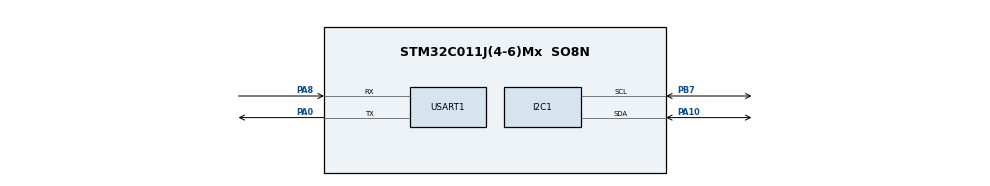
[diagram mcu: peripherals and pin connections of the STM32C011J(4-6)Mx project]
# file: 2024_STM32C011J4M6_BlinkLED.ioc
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I2C1.Timing=0x20303E5D
Mcu.Family=STM32C0
Mcu.Name=STM32C011J(4-6)Mx
Mcu.Package=SO8N
PA0.Mode=Asynchronous
PA0.Signal=USART1_TX
PA10\ [PA12].Mode=I2C
PA10\ [PA12].Signal=I2C1_SDA
PA13.Mode=Serial_Wire
PA13.Signal=DEBUG_SWDIO
PA14-BOOT0.Mode=Serial_Wire
PA14-BOOT0.Signal=DEBUG_SWCLK
PA8.Mode=Asynchronous
PA8.Signal=USART1_RX
PA8__PA11\ [PA9].StandardMode=true
PB7.Mode=I2C
PB7.Signal=I2C1_SCL
PC14-OSCX_IN\ (PC14)__PB7.StandardMode=true
PC15-OSCX_OUT\ (PC15)__PA14-BOOT0__PB6.StandardMode=true
PF2-NRST__PA0__PA1__PA2.StandardMode=true
ProjectManager.HeapSize=0x200
ProjectManager.StackSize=0x400
ProjectManager.TargetToolchain=STM32CubeIDE
RCC.ADCFreq_Value=48000000
RCC.AHBFreq_Value=48000000
RCC.CortexFreq_Value=48000000
RCC.EXTERNAL_CLOCK_VALUE=12288000
RCC.HCLKFreq_Value=48000000
RCC.HSE_VALUE=8000000
RCC.HSISYSCLKDivider=RCC_HSI_DIV1
RCC.HSI_VALUE=48000000
RCC.LSE_VALUE=32768
RCC.SYSCLKFreq_VALUE=48000000
USART1.DMADisableonRxErrorParam=ADVFEATURE_DMA_ENABLEONRXERROR
USART1.OverrunDisableParam=ADVFEATURE_OVERRUN_ENABLE
USART1.SwapParam=ADVFEATURE_SWAP_DISABLE
USART1.VirtualMode-Asynchronous=VM_ASYNC
VP_SYS_VS_PINREMAP_10_12.Mode=PINREMAP_10_12
board=custom

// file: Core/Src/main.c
/* USER CODE BEGIN Header */
/**
  ******************************************************************************
  * @file           : main.c
  * @brief          : Main program body
  ******************************************************************************
  * @attention
  *
  * Copyright (c) 2024 STMicroelectronics.
  * All rights reserved.
  *
  * This software is licensed under terms that can be found in the LICENSE file
  * in the root directory of this software component.
  * If no LICENSE file comes with this software, it is provided AS-IS.
  *
  ******************************************************************************
  */
/* USER CODE END Header */
#include "main.h"

I2C_HandleTypeDef hi2c1;

UART_HandleTypeDef huart1;

void SystemClock_Config(void);
static void MX_GPIO_Init(void);
static void MX_USART1_UART_Init(void);
static void MX_I2C1_Init(void);

int main(void)
{

  /* USER CODE BEGIN 1 */
	uint8_t rxData;
  /* USER CODE END 1 */

  /* MCU Configuration--------------------------------------------------------*/

  /* Reset of all peripherals, Initializes the Flash interface and the Systick. */
  HAL_Init();

  /* Configure the system clock */
  SystemClock_Config();

  /* Initialize all configured peripherals */
  MX_GPIO_Init();
  MX_USART1_UART_Init();
  MX_I2C1_Init();

  /* Infinite loop */
  /* USER CODE BEGIN WHILE */
  while (1)
  {
	  // Check if serial data is available
	  if( HAL_UART_Receive(&huart1, &rxData, 1, HAL_MAX_DELAY) == HAL_OK ) {
	  	  HAL_UART_Transmit(&huart1, &rxData, sizeof(rxData), HAL_MAX_DELAY);
	  }

    /* USER CODE END WHILE */

  }
}

void SystemClock_Config(void)
{
  RCC_OscInitTypeDef RCC_OscInitStruct = {0};
  RCC_ClkInitTypeDef RCC_ClkInitStruct = {0};

  /** Initializes the RCC Oscillators according to the specified parameters
  * in the RCC_OscInitTypeDef structure.
  */
  RCC_OscInitStruct.OscillatorType = RCC_OSCILLATORTYPE_HSI;
  RCC_OscInitStruct.HSIState = RCC_HSI_ON;
  RCC_OscInitStruct.HSIDiv = RCC_HSI_DIV1;
  RCC_OscInitStruct.HSICalibrationValue = RCC_HSICALIBRATION_DEFAULT;
  if (HAL_RCC_OscConfig(&RCC_OscInitStruct) != HAL_OK)
  {
    Error_Handler();
  }

  /** Initializes the CPU, AHB and APB buses clocks
  */
  RCC_ClkInitStruct.ClockType = RCC_CLOCKTYPE_HCLK|RCC_CLOCKTYPE_SYSCLK
                              |RCC_CLOCKTYPE_PCLK1;
  RCC_ClkInitStruct.SYSCLKSource = RCC_SYSCLKSOURCE_HSI;
  RCC_ClkInitStruct.SYSCLKDivider = RCC_SYSCLK_DIV1;
  RCC_ClkInitStruct.AHBCLKDivider = RCC_HCLK_DIV1;
  RCC_ClkInitStruct.APB1CLKDivider = RCC_APB1_DIV1;

  if (HAL_RCC_ClockConfig(&RCC_ClkInitStruct, FLASH_LATENCY_1) != HAL_OK)
  {
    Error_Handler();
  }
}

static void MX_I2C1_Init(void)
{

  hi2c1.Instance = I2C1;
  hi2c1.Init.Timing = 0x20303E5D;
  hi2c1.Init.OwnAddress1 = 0;
  hi2c1.Init.AddressingMode = I2C_ADDRESSINGMODE_7BIT;
  hi2c1.Init.DualAddressMode = I2C_DUALADDRESS_DISABLE;
  hi2c1.Init.OwnAddress2 = 0;
  hi2c1.Init.OwnAddress2Masks = I2C_OA2_NOMASK;
  hi2c1.Init.GeneralCallMode = I2C_GENERALCALL_DISABLE;
  hi2c1.Init.NoStretchMode = I2C_NOSTRETCH_DISABLE;
  if (HAL_I2C_Init(&hi2c1) != HAL_OK)
  {
    Error_Handler();
  }

  /** Configure Analogue filter
  */
  if (HAL_I2CEx_ConfigAnalogFilter(&hi2c1, I2C_ANALOGFILTER_ENABLE) != HAL_OK)
  {
    Error_Handler();
  }

  /** Configure Digital filter
  */
  if (HAL_I2CEx_ConfigDigitalFilter(&hi2c1, 0) != HAL_OK)
  {
    Error_Handler();
  }

}

static void MX_USART1_UART_Init(void)
{

  huart1.Instance = USART1;
  huart1.Init.BaudRate = 115200;
  huart1.Init.WordLength = UART_WORDLENGTH_8B;
  huart1.Init.StopBits = UART_STOPBITS_1;
  huart1.Init.Parity = UART_PARITY_NONE;
  huart1.Init.Mode = UART_MODE_TX_RX;
  huart1.Init.HwFlowCtl = UART_HWCONTROL_NONE;
  huart1.Init.OverSampling = UART_OVERSAMPLING_16;
  huart1.Init.OneBitSampling = UART_ONE_BIT_SAMPLE_DISABLE;
  huart1.Init.ClockPrescaler = UART_PRESCALER_DIV1;
  huart1.AdvancedInit.AdvFeatureInit = UART_ADVFEATURE_NO_INIT;
  if (HAL_UART_Init(&huart1) != HAL_OK)
  {
    Error_Handler();
  }
  if (HAL_UARTEx_SetTxFifoThreshold(&huart1, UART_TXFIFO_THRESHOLD_1_8) != HAL_OK)
  {
    Error_Handler();
  }
  if (HAL_UARTEx_SetRxFifoThreshold(&huart1, UART_RXFIFO_THRESHOLD_1_8) != HAL_OK)
  {
    Error_Handler();
  }
  if (HAL_UARTEx_DisableFifoMode(&huart1) != HAL_OK)
  {
    Error_Handler();
  }

}

static void MX_GPIO_Init(void)
{

  /* GPIO Ports Clock Enable */
  __HAL_RCC_GPIOB_CLK_ENABLE();
  __HAL_RCC_GPIOA_CLK_ENABLE();

}

void Error_Handler(void)
{
  __disable_irq();
  while (1)
  {
  }
}
